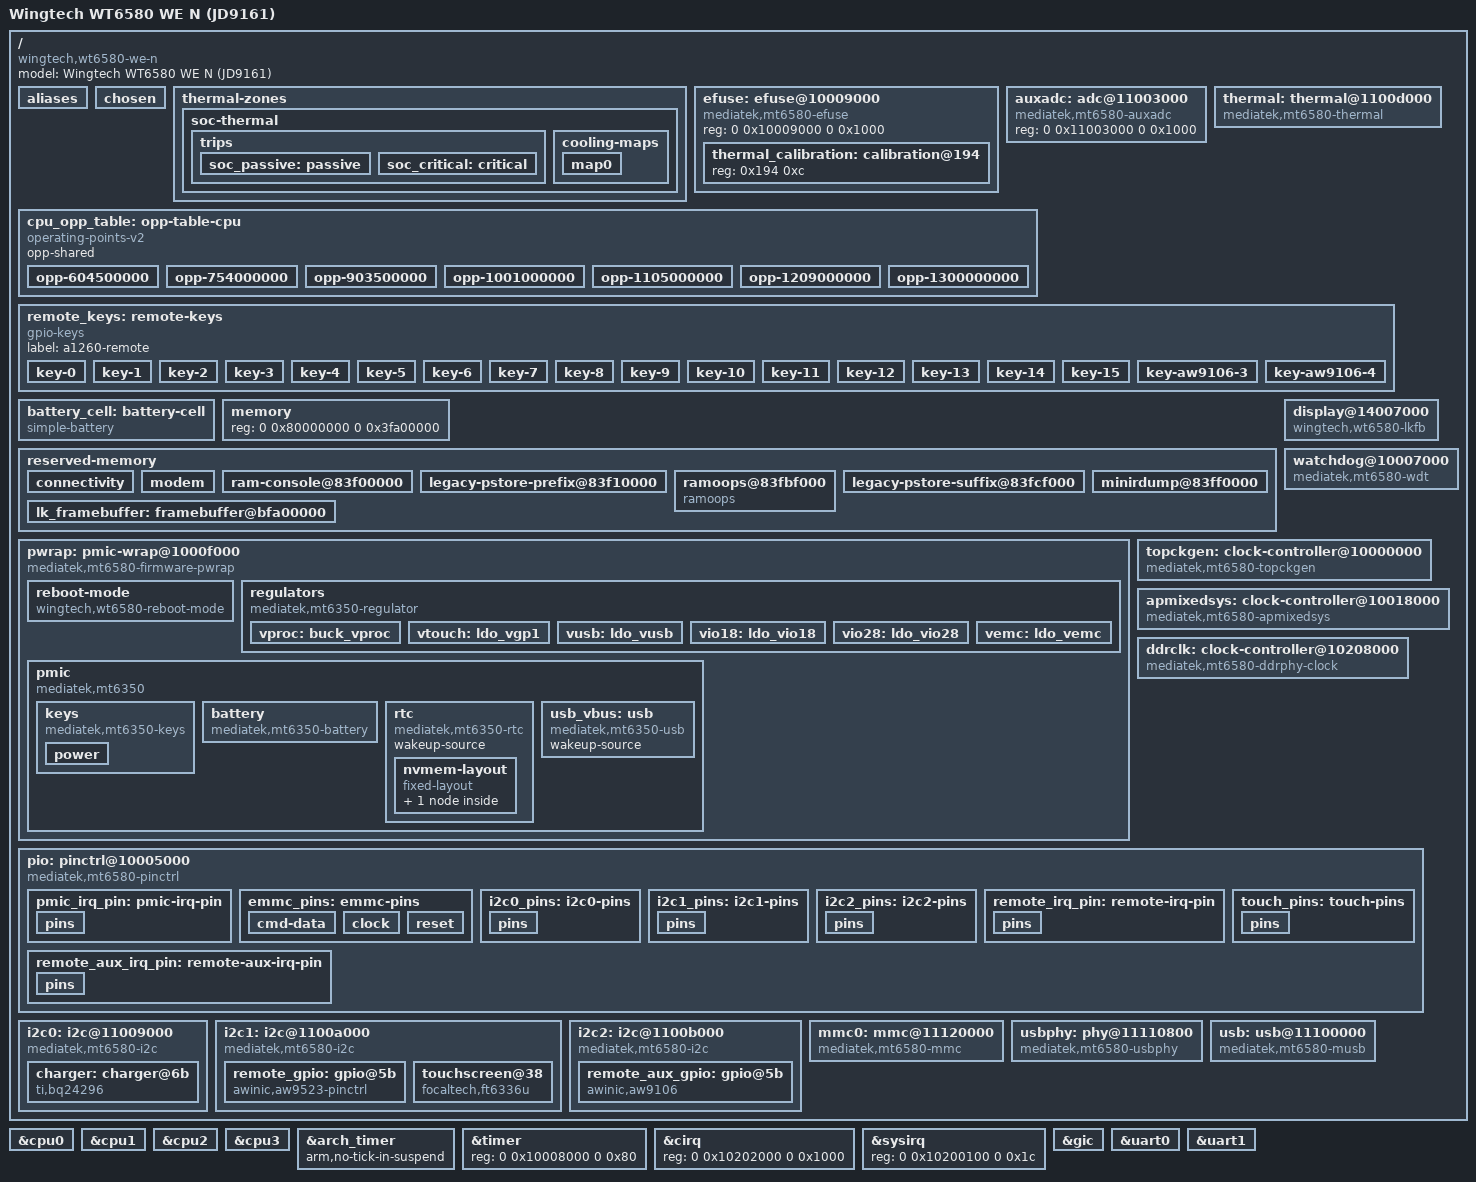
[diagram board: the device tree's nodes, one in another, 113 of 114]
// SPDX-License-Identifier: GPL-2.0-only
/dts-v1/;
#include "mt6580.dtsi"
#include <dt-bindings/clock/mt6580-clk.h>
#include <dt-bindings/gpio/gpio.h>
#include <dt-bindings/input/input.h>
#include <dt-bindings/pinctrl/mt65xx.h>
#include <dt-bindings/thermal/thermal.h>

/ {
	model = "Wingtech WT6580 WE N (JD9161)";
	compatible = "wingtech,wt6580-we-n", "mediatek,mt6580";
	/* Match the cell widths used by the vendor LK's DT fixups. */
	#address-cells = <2>;
	#size-cells = <2>;

	aliases {
		serial0 = &uart0;
		serial1 = &uart1;
		mmc0 = &mmc0;
		i2c0 = &i2c0;
		i2c1 = &i2c1;
		i2c2 = &i2c2;
	};

	chosen {
		stdout-path = "serial0:921600n8";
		bootargs = "earlycon console=ttyS0,921600n8 rdinit=/init";
	};

	/* Conservative board limits while higher CPU OPPs are being qualified. */
	thermal-zones {
		soc-thermal {
			polling-delay-passive = <250>;
			polling-delay = <1000>;
			thermal-sensors = <&thermal 0>;
			trips {
				soc_passive: passive {
					temperature = <75000>;
					hysteresis = <5000>;
					type = "passive";
				};
				soc_critical: critical {
					temperature = <105000>;
					hysteresis = <2000>;
					type = "critical";
				};
			};
			cooling-maps {
				map0 {
					trip = <&soc_passive>;
					cooling-device = <&cpu0 THERMAL_NO_LIMIT THERMAL_NO_LIMIT>;
				};
			};
		};
	};

	efuse: efuse@10009000 {
		compatible = "mediatek,mt6580-efuse", "mediatek,efuse";
		reg = <0 0x10009000 0 0x1000>;
		#address-cells = <1>;
		#size-cells = <1>;
		thermal_calibration: calibration@194 {
			reg = <0x194 0xc>;
		};
	};

	auxadc: adc@11003000 {
		compatible = "mediatek,mt6580-auxadc";
		reg = <0 0x11003000 0 0x1000>;
	};

	thermal: thermal@1100d000 {
		compatible = "mediatek,mt6580-thermal";
		reg = <0 0x1100d000 0 0x1000>;
		interrupts = <GIC_SPI 37 IRQ_TYPE_LEVEL_LOW>;
		clocks = <&topckgen CLK_MT6580_TOP_THERM>,
			 <&topckgen CLK_MT6580_TOP_AUXADC>;
		clock-names = "therm", "auxadc";
		mediatek,auxadc = <&auxadc>;
		mediatek,apmixedsys = <&apmixedsys>;
		nvmem-cells = <&thermal_calibration>;
		nvmem-cell-names = "calibration-data";
		#thermal-sensor-cells = <1>;
	};

	cpu_opp_table: opp-table-cpu {
		compatible = "operating-points-v2";
		opp-shared;
		/* MT6580 BSP level-0 (1.3 GHz segment), without undervolting. */
		opp-604500000 {
			opp-hz = /bits/ 64 <604500000>;
			opp-microvolt = <1150000>;
			clock-latency-ns = <100000>;
			opp-suspend;
		};
		opp-754000000 {
			opp-hz = /bits/ 64 <754000000>;
			opp-microvolt = <1150000>;
			clock-latency-ns = <100000>;
		};
		opp-903500000 {
			opp-hz = /bits/ 64 <903500000>;
			opp-microvolt = <1150000>;
			clock-latency-ns = <100000>;
		};
		opp-1001000000 {
			opp-hz = /bits/ 64 <1001000000>;
			opp-microvolt = <1150000>;
			clock-latency-ns = <100000>;
		};
		opp-1105000000 {
			opp-hz = /bits/ 64 <1105000000>;
			opp-microvolt = <1193750>;
			clock-latency-ns = <100000>;
		};
		opp-1209000000 {
			opp-hz = /bits/ 64 <1209000000>;
			opp-microvolt = <1225000>;
			clock-latency-ns = <100000>;
		};
		opp-1300000000 {
			opp-hz = /bits/ 64 <1300000000>;
			/* BSP requests 1.30625 V, but this PMIC reports code 0x60
			 * (1.3 V) even with target 0x61. Use the measured plateau.
			 */
			opp-microvolt = <1300000>;
			clock-latency-ns = <100000>;
		};
	};

	/* Native GPIO/scan-code order recovered from the original 3.18 kernel. */
	remote_keys: remote-keys {
		compatible = "gpio-keys";
		label = "a1260-remote";

		key-0 {
			label = "remote-aw9523-0";
			linux,code = <KEY_RIGHT>;
			gpios = <&remote_gpio 0 GPIO_ACTIVE_HIGH>;
			debounce-interval = <16>;
		};

		key-1 {
			label = "remote-aw9523-1";
			linux,code = <KEY_F2>;
			gpios = <&remote_gpio 1 GPIO_ACTIVE_HIGH>;
			debounce-interval = <16>;
		};

		key-2 {
			label = "remote-aw9523-2";
			linux,code = <KEY_UP>;
			gpios = <&remote_gpio 2 GPIO_ACTIVE_HIGH>;
			debounce-interval = <16>;
		};

		key-3 {
			label = "remote-aw9523-3";
			linux,code = <KEY_ENTER>;
			gpios = <&remote_gpio 3 GPIO_ACTIVE_HIGH>;
			debounce-interval = <16>;
		};

		key-4 {
			label = "remote-aw9523-4";
			linux,code = <KEY_F1>;
			gpios = <&remote_gpio 4 GPIO_ACTIVE_HIGH>;
			debounce-interval = <16>;
		};

		key-5 {
			label = "remote-aw9523-5";
			linux,code = <KEY_LEFT>;
			gpios = <&remote_gpio 5 GPIO_ACTIVE_HIGH>;
			debounce-interval = <16>;
		};

		key-6 {
			label = "remote-aw9523-6";
			linux,code = <KEY_DOWN>;
			gpios = <&remote_gpio 6 GPIO_ACTIVE_HIGH>;
			debounce-interval = <16>;
		};

		key-7 {
			label = "remote-aw9523-7";
			linux,code = <KEY_BACK>;
			gpios = <&remote_gpio 7 GPIO_ACTIVE_HIGH>;
			debounce-interval = <16>;
		};

		key-8 {
			label = "remote-aw9523-8";
			linux,code = <KEY_MENU>;
			gpios = <&remote_gpio 8 GPIO_ACTIVE_HIGH>;
			debounce-interval = <16>;
		};

		key-9 {
			label = "remote-aw9523-9";
			linux,code = <KEY_F5>;
			gpios = <&remote_gpio 9 GPIO_ACTIVE_HIGH>;
			debounce-interval = <16>;
		};

		key-10 {
			label = "remote-aw9523-10";
			linux,code = <KEY_F4>;
			gpios = <&remote_gpio 10 GPIO_ACTIVE_HIGH>;
			debounce-interval = <16>;
		};

		key-11 {
			label = "remote-aw9523-11";
			linux,code = <KEY_F3>;
			gpios = <&remote_gpio 11 GPIO_ACTIVE_HIGH>;
			debounce-interval = <16>;
		};

		key-12 {
			label = "remote-aw9523-12";
			linux,code = <KEY_VOLUMEUP>;
			gpios = <&remote_gpio 12 GPIO_ACTIVE_HIGH>;
			debounce-interval = <16>;
		};

		key-13 {
			label = "remote-aw9523-13";
			linux,code = <KEY_VOLUMEDOWN>;
			gpios = <&remote_gpio 13 GPIO_ACTIVE_HIGH>;
			debounce-interval = <16>;
		};

		key-14 {
			label = "remote-aw9523-14";
			linux,code = <KEY_HOME>;
			gpios = <&remote_gpio 14 GPIO_ACTIVE_HIGH>;
			debounce-interval = <16>;
		};

		key-15 {
			label = "remote-aw9523-15";
			linux,code = <KEY_F6>;
			gpios = <&remote_gpio 15 GPIO_ACTIVE_HIGH>;
			debounce-interval = <16>;
		};

		key-aw9106-3 {
			label = "remote-aw9106-3";
			linux,code = <KEY_F8>;
			gpios = <&remote_aux_gpio 3 GPIO_ACTIVE_HIGH>;
			debounce-interval = <16>;
		};

		key-aw9106-4 {
			label = "remote-aw9106-4";
			linux,code = <KEY_F7>;
			gpios = <&remote_aux_gpio 4 GPIO_ACTIVE_HIGH>;
			debounce-interval = <16>;
		};
	};

	/* Cell label: 1850 mAh, nominal 3.7 V, 6.845 Wh.
	 * Charge limits and characterization are separate from nominal voltage.
	 */
	battery_cell: battery-cell {
		compatible = "simple-battery";
		device-chemistry = "lithium-ion";
		charge-full-design-microamp-hours = <1850000>;
		energy-full-design-microwatt-hours = <6845000>;
		voltage-min-design-microvolt = <3400000>;
		voltage-max-design-microvolt = <4200000>;
		precharge-current-microamp = <512000>;
		charge-term-current-microamp = <256000>;
		constant-charge-current-max-microamp = <512000>;
		constant-charge-voltage-max-microvolt = <4200000>;
	};

	/* Keep the vendor /memory path for old bootloader memory fixups. */
	memory {
		device_type = "memory";
		/* Captured from the running device, excluding the top 6 MiB. */
		reg = <0 0x80000000 0 0x3fa00000>;
	};

	reserved-memory {
		#address-cells = <2>;
		#size-cells = <2>;
		ranges;

		/* Keep the vendor kernel's dynamic connectivity/modem carve-outs. */
		connectivity {
			size = <0 0x200000>;
			alignment = <0 0x200000>;
			no-map;
		};

		modem {
			size = <0 0x1800000>;
			alignment = <0 0x2000000>;
			alloc-ranges = <0 0x80000000 0 0x80000000>;
			no-map;
		};

		ram-console@83f00000 {
			reg = <0 0x83f00000 0 0x10000>;
			no-map;
		};

		legacy-pstore-prefix@83f10000 {
			reg = <0 0x83f10000 0 0xaf000>;
			no-map;
		};

		/* Match the vendor ramoops console zone for recovery after reboot. */
		ramoops@83fbf000 {
			compatible = "ramoops";
			reg = <0 0x83fbf000 0 0x10000>;
			/* Avoid a small-page island beside a section in one ARM PMD. */
			no-map;
			console-size = <0x10000>;
		};

		legacy-pstore-suffix@83fcf000 {
			reg = <0 0x83fcf000 0 0x31000>;
			no-map;
		};

		minirdump@83ff0000 {
			reg = <0 0x83ff0000 0 0x10000>;
			no-map;
		};

		/* Packed live atag,videolfb; top 6 MiB is outside /memory. */
		lk_framebuffer: framebuffer@bfa00000 {
			reg = <0 0xbfa00000 0 0x600000>;
			no-map;
		};
	};

	/* Read existing scanout registers; retain LK's clocks, PHY and panel. */
	display@14007000 {
		compatible = "wingtech,wt6580-lkfb";
		reg = <0 0x14007000 0 0x1000>,
		      <0 0x14009000 0 0x1000>,
		      <0 0x14012000 0 0x1000>,
		      <0 0x14018000 0 0x1000>,
		      <0 0x14000000 0 0x1000>;
		reg-names = "ovl", "rdma", "dsi", "mipi", "mmsys";
		memory-region = <&lk_framebuffer>;
	};

	watchdog@10007000 {
		compatible = "mediatek,mt6580-wdt", "mediatek,mt6589-wdt";
		reg = <0 0x10007000 0 0x100>;
		timeout-sec = <30>;
	};

	pwrap: pmic-wrap@1000f000 {
		compatible = "mediatek,mt6580-firmware-pwrap";
		reg = <0 0x1000f000 0 0x1000>;
		clocks = <&topckgen CLK_MT6580_TOP_PMIC_SPI>,
			 <&topckgen CLK_MT6580_TOP_PMIC_26M>;
		clock-names = "spi", "26m";

		reboot-mode {
			compatible = "wingtech,wt6580-reboot-mode";
		};

		regulators {
			compatible = "mediatek,mt6350-regulator";

			vproc: buck_vproc {
				regulator-name = "vproc";
				/* BSP level-0 OPP range; never undervolt the MAINPLL handover. */
				regulator-min-microvolt = <1150000>;
				regulator-max-microvolt = <1300000>;
				regulator-always-on;
				regulator-boot-on;
			};

			vtouch: ldo_vgp1 {
				regulator-name = "vtouch";
				regulator-min-microvolt = <2800000>;
				regulator-max-microvolt = <2800000>;
			};

			vusb: ldo_vusb {
				regulator-name = "vusb";
				regulator-min-microvolt = <3300000>;
				regulator-max-microvolt = <3300000>;
				regulator-boot-on;
			};

			/* Shared board rails: consumers are not all identified yet. */
			vio18: ldo_vio18 {
				regulator-name = "vio18";
				regulator-min-microvolt = <1800000>;
				regulator-max-microvolt = <1800000>;
				regulator-boot-on;
				regulator-always-on;
			};

			vio28: ldo_vio28 {
				regulator-name = "vio28";
				regulator-min-microvolt = <2800000>;
				regulator-max-microvolt = <2800000>;
				regulator-boot-on;
				regulator-always-on;
			};

			vemc: ldo_vemc {
				regulator-name = "vemc";
				/* Preserve the measured firmware VOSEL=1 (3.3 V). */
				regulator-min-microvolt = <3300000>;
				regulator-max-microvolt = <3300000>;
				regulator-boot-on;
				regulator-always-on;
			};
		};

		pmic {
			compatible = "mediatek,mt6350";
			interrupt-parent = <&pio>;
			/* Old DT names GPIO13; its PMIC function routes to EINT17. */
			interrupts = <17 IRQ_TYPE_LEVEL_HIGH>;
			pinctrl-names = "default";
			pinctrl-0 = <&pmic_irq_pin>;
			interrupt-controller;
			#interrupt-cells = <2>;

			keys {
				compatible = "mediatek,mt6350-keys";
				mediatek,long-press-mode = <1>;
				power-off-time-sec = <0>;
				power {
					linux,keycodes = <KEY_POWER>;
					wakeup-source;
				};
			};

			battery {
				compatible = "mediatek,mt6350-battery";
				monitored-battery = <&battery_cell>;
				power-supplies = <&charger>;
			nvmem-cells = <&battery_soc>;
			nvmem-cell-names = "soc";
			};

			rtc {
				compatible = "mediatek,mt6350-rtc";
				wakeup-source;

				nvmem-layout {
					compatible = "fixed-layout";
					#address-cells = <1>;
					#size-cells = <1>;

					battery_soc: soc@0 {
						reg = <0 1>;
					};
				};
			};

			usb_vbus: usb {
				compatible = "mediatek,mt6350-usb";
				wakeup-source;
			};
		};
	};

	topckgen: clock-controller@10000000 {
		compatible = "mediatek,mt6580-topckgen";
		reg = <0 0x10000000 0 0x1000>;
		clocks = <&apmixedsys CLK_MT6580_APMIXED_MAINPLL>,
			 <&apmixedsys CLK_MT6580_APMIXED_UNIVPLL>, <&ddrclk>;
		clock-names = "mainpll", "univpll", "memory";
		#clock-cells = <1>;
	};

	apmixedsys: clock-controller@10018000 {
		compatible = "mediatek,mt6580-apmixedsys";
		reg = <0 0x10018000 0 0x1000>, <0 0x10001000 0 0x1000>;
		#clock-cells = <1>;
	};

	ddrclk: clock-controller@10208000 {
		compatible = "mediatek,mt6580-ddrphy-clock";
		reg = <0 0x10208000 0 0x1000>,
		      <0 0x10207000 0 0x1000>,
		      <0 0x10206000 0 0x1000>;
		reg-names = "ddrphy", "dramc-ao", "dramc-nao";
		clocks = <&uart_clk>;
		clock-names = "xtal";
		#clock-cells = <0>;
	};

	pio: pinctrl@10005000 {
		compatible = "mediatek,mt6580-pinctrl";
		reg = <0 0x10005000 0 0x1000>,
		      <0 0x10014000 0 0x1000>,
		      <0 0x10015000 0 0x1000>,
		      <0 0x10016000 0 0x1000>,
		      <0 0x10017000 0 0x1000>,
		      <0 0x1000b000 0 0x1000>;
		reg-names = "gpio", "iocfg-t", "iocfg-b", "iocfg-l", "iocfg-r", "eint";
		gpio-controller;
		#gpio-cells = <2>;
		gpio-ranges = <&pio 0 0 93>;
		interrupt-controller;
		#interrupt-cells = <2>;
		interrupts = <GIC_SPI 94 IRQ_TYPE_LEVEL_HIGH>;

		pmic_irq_pin: pmic-irq-pin {
			pins {
				pinmux = <(MTK_PIN_NO(13) | 1)>;
				input-enable;
				bias-disable;
			};
		};

		emmc_pins: emmc-pins {
			/* Match BSP drive code 2, input buffers, pulls and pad delays. */
			cmd-data {
				pinmux = <(MTK_PIN_NO(42) | 1)>, <(MTK_PIN_NO(43) | 1)>,
					 <(MTK_PIN_NO(44) | 1)>, <(MTK_PIN_NO(45) | 1)>,
					 <(MTK_PIN_NO(46) | 1)>, <(MTK_PIN_NO(47) | 1)>,
					 <(MTK_PIN_NO(48) | 1)>, <(MTK_PIN_NO(49) | 1)>,
					 <(MTK_PIN_NO(50) | 1)>;
				input-enable;
				input-schmitt-enable;
				drive-strength = <6>;
				bias-pull-up = <MTK_PUPD_SET_R1R0_01>;
				mediatek,tdsel = <10>;
				mediatek,rdsel = <0>;
			};

			clock {
				pinmux = <(MTK_PIN_NO(41) | 1)>;
				input-enable;
				input-schmitt-enable;
				drive-strength = <6>;
				bias-pull-down = <MTK_PUPD_SET_R1R0_10>;
			};

			reset {
				pinmux = <(MTK_PIN_NO(51) | 0)>;
				input-enable;
				input-schmitt-enable;
				drive-strength = <6>;
				bias-pull-up = <MTK_PUPD_SET_R1R0_01>;
			};
		};

		i2c0_pins: i2c0-pins {
			pins {
				pinmux = <(MTK_PIN_NO(58) | 1)>,
					 <(MTK_PIN_NO(61) | 1)>;
				input-enable;
			};
		};

		i2c1_pins: i2c1-pins {
			pins {
				pinmux = <(MTK_PIN_NO(59) | 1)>,
					 <(MTK_PIN_NO(62) | 1)>;
				input-enable;
			};
		};

		i2c2_pins: i2c2-pins {
			pins {
				pinmux = <(MTK_PIN_NO(60) | 1)>,
					 <(MTK_PIN_NO(63) | 1)>;
				input-enable;
			};
		};

		remote_irq_pin: remote-irq-pin {
			pins {
				pinmux = <(MTK_PIN_NO(4) | 6)>;
				input-enable;
				bias-disable;
			};
		};

		remote_aux_irq_pin: remote-aux-irq-pin {
			pins {
				pinmux = <(MTK_PIN_NO(6) | 6)>;
				input-enable;
				bias-disable;
			};
		};

		touch_pins: touch-pins {
			pins {
				pinmux = <(MTK_PIN_NO(5) | 6)>;
				input-enable;
				bias-disable;
			};
		};
	};


	i2c0: i2c@11009000 {
		compatible = "mediatek,mt6580-i2c";
		reg = <0 0x11009000 0 0x1000>, <0 0x11000180 0 0x80>;
		interrupts = <GIC_SPI 40 IRQ_TYPE_LEVEL_LOW>;
		clocks = <&topckgen CLK_MT6580_TOP_I2C0>,
			 <&topckgen CLK_MT6580_TOP_APDMA>;
		clock-names = "main", "dma";
		clock-div = <10>;
		clock-frequency = <100000>;
		pinctrl-names = "default";
		pinctrl-0 = <&i2c0_pins>;
		#address-cells = <1>;
		#size-cells = <0>;

		charger: charger@6b {
			compatible = "ti,bq24296";
			reg = <0x6b>;
			/* Original board has no independent charger IRQ in its DT. */
			poll-interval = <2000>;
			input-current-limit-microamp = <500000>;
			disable-reset;
			omit-battery-class;
			monitored-battery = <&battery_cell>;
			ti,system-minimum-microvolt = <3500000>;
		};
	};

	i2c1: i2c@1100a000 {
		compatible = "mediatek,mt6580-i2c";
		reg = <0 0x1100a000 0 0x1000>, <0 0x11000200 0 0x80>;
		interrupts = <GIC_SPI 41 IRQ_TYPE_LEVEL_LOW>;
		clocks = <&topckgen CLK_MT6580_TOP_I2C1>,
			 <&topckgen CLK_MT6580_TOP_APDMA>;
		clock-names = "main", "dma";
		clock-div = <10>;
		clock-frequency = <100000>;
		pinctrl-names = "default";
		pinctrl-0 = <&i2c1_pins>;
		#address-cells = <1>;
		#size-cells = <0>;

		remote_gpio: gpio@5b {
			compatible = "awinic,aw9523-pinctrl";
			reg = <0x5b>;
			interrupt-parent = <&pio>;
			interrupts = <4 IRQ_TYPE_LEVEL_LOW>;
			interrupt-controller;
			#interrupt-cells = <2>;
			gpio-controller;
			#gpio-cells = <2>;
			gpio-ranges = <&remote_gpio 0 0 16>;
			/* This driver expresses RSTN as raw low then raw high. */
			reset-gpios = <&pio 72 GPIO_ACTIVE_HIGH>;
			pinctrl-names = "default";
			pinctrl-0 = <&remote_irq_pin>;
		};

		touchscreen@38 {
			compatible = "focaltech,ft6336u";
			reg = <0x38>;
			interrupt-parent = <&pio>;
			interrupts = <5 IRQ_TYPE_EDGE_FALLING>;
			reset-gpios = <&pio 2 GPIO_ACTIVE_LOW>;
			pinctrl-names = "default";
			pinctrl-0 = <&touch_pins>;
			vcc-supply = <&vtouch>;
			touchscreen-size-x = <480>;
			touchscreen-size-y = <800>;
		};
	};

	i2c2: i2c@1100b000 {
		compatible = "mediatek,mt6580-i2c";
		reg = <0 0x1100b000 0 0x1000>, <0 0x11000280 0 0x80>;
		interrupts = <GIC_SPI 42 IRQ_TYPE_LEVEL_LOW>;
		clocks = <&topckgen CLK_MT6580_TOP_I2C2>,
			 <&topckgen CLK_MT6580_TOP_APDMA>;
		clock-names = "main", "dma";
		clock-div = <10>;
		clock-frequency = <100000>;
		pinctrl-names = "default";
		pinctrl-0 = <&i2c2_pins>;
		#address-cells = <1>;
		#size-cells = <0>;

		remote_aux_gpio: gpio@5b {
			compatible = "awinic,aw9106";
			reg = <0x5b>;
			interrupt-parent = <&pio>;
			interrupts = <6 IRQ_TYPE_LEVEL_LOW>;
			interrupt-controller;
			#interrupt-cells = <2>;
			gpio-controller;
			#gpio-cells = <2>;
			reset-gpios = <&pio 73 GPIO_ACTIVE_LOW>;
			pinctrl-names = "default";
			pinctrl-0 = <&remote_aux_irq_pin>;
		};
	};

	mmc0: mmc@11120000 {
		compatible = "mediatek,mt6580-mmc";
		reg = <0 0x11120000 0 0x10000>;
		interrupts = <GIC_SPI 38 IRQ_TYPE_LEVEL_LOW>;
		clocks = <&topckgen CLK_MT6580_TOP_MSDC0>,
			 <&topckgen CLK_MT6580_TOP_MSDC0>;
		clock-names = "source", "hclk";
		bus-width = <8>;
		max-frequency = <52000000>;
		cap-mmc-highspeed;
		/* Original board register_setting has all three sample edges = 1. */
		mediatek,cmd-falling-edge;
		mediatek,data-falling-edge;
		mediatek,crc-falling-edge;
		non-removable;
		no-sd;
		no-sdio;
		vmmc-supply = <&vemc>;
		/* Fixed I/O rail: no 1.8 V negotiation or HS200/HS400 yet. */
		no-1-8-v;
		pinctrl-names = "default", "state_uhs";
		pinctrl-0 = <&emmc_pins>;
		pinctrl-1 = <&emmc_pins>;
	};

	usbphy: phy@11110800 {
		compatible = "mediatek,mt6580-usbphy";
		reg = <0 0x11110800 0 0x800>;
		clocks = <&apmixedsys CLK_MT6580_APMIXED_USB48M>;
		clock-names = "ref";
		phy-supply = <&vusb>;
		#phy-cells = <0>;
	};

	usb: usb@11100000 {
		compatible = "mediatek,mt6580-musb", "mediatek,mtk-musb";
		reg = <0 0x11100000 0 0x1000>;
		interrupts = <GIC_SPI 32 IRQ_TYPE_LEVEL_LOW>;
		interrupt-names = "mc";
		clocks = <&topckgen CLK_MT6580_TOP_USB>,
			 <&topckgen CLK_MT6580_TOP_USB>,
			 <&apmixedsys CLK_MT6580_APMIXED_UNIV48M>;
		clock-names = "main", "mcu", "univpll";
		phys = <&usbphy>;
		extcon = <&usb_vbus>;
		dr_mode = "peripheral";
	};
};

/* All inherited MMIO ranges must follow the board's two-cell root. */
&cpu0 {
	#cooling-cells = <2>;
	clocks = <&apmixedsys CLK_MT6580_APMIXED_CPU>;
	operating-points-v2 = <&cpu_opp_table>;
	cpu-supply = <&vproc>;
	capacity-dmips-mhz = <1024>;
};

&cpu1 {
	clocks = <&apmixedsys CLK_MT6580_APMIXED_CPU>;
	operating-points-v2 = <&cpu_opp_table>;
	cpu-supply = <&vproc>;
	capacity-dmips-mhz = <1024>;
};

&cpu2 {
	clocks = <&apmixedsys CLK_MT6580_APMIXED_CPU>;
	operating-points-v2 = <&cpu_opp_table>;
	cpu-supply = <&vproc>;
	capacity-dmips-mhz = <1024>;
};

&cpu3 {
	clocks = <&apmixedsys CLK_MT6580_APMIXED_CPU>;
	operating-points-v2 = <&cpu_opp_table>;
	cpu-supply = <&vproc>;
	capacity-dmips-mhz = <1024>;
};

&arch_timer {
	/* Do not assume the 13 MHz counter survives future system-clock stop.
	 * The MT6350 RTC supplies suspend-time compensation through RTC core.
	 */
	arm,no-tick-in-suspend;
};

&timer {
	reg = <0 0x10008000 0 0x80>;
};

&cirq {
	reg = <0 0x10202000 0 0x1000>;
	#address-cells = <0>;
};

&sysirq {
	reg = <0 0x10200100 0 0x1c>;
	#address-cells = <0>;
};

&gic {
	reg = <0 0x10211000 0 0x1000>,
	      <0 0x10212000 0 0x2000>,
	      <0 0x10214000 0 0x2000>,
	      <0 0x10216000 0 0x2000>;
	#address-cells = <0>;
};

&uart0 {
	reg = <0 0x11005000 0 0x400>;
	clocks = <&topckgen CLK_MT6580_TOP_UART0>;
	status = "okay";
};

&uart1 {
	reg = <0 0x11006000 0 0x400>;
	clocks = <&topckgen CLK_MT6580_TOP_UART1>;
};
